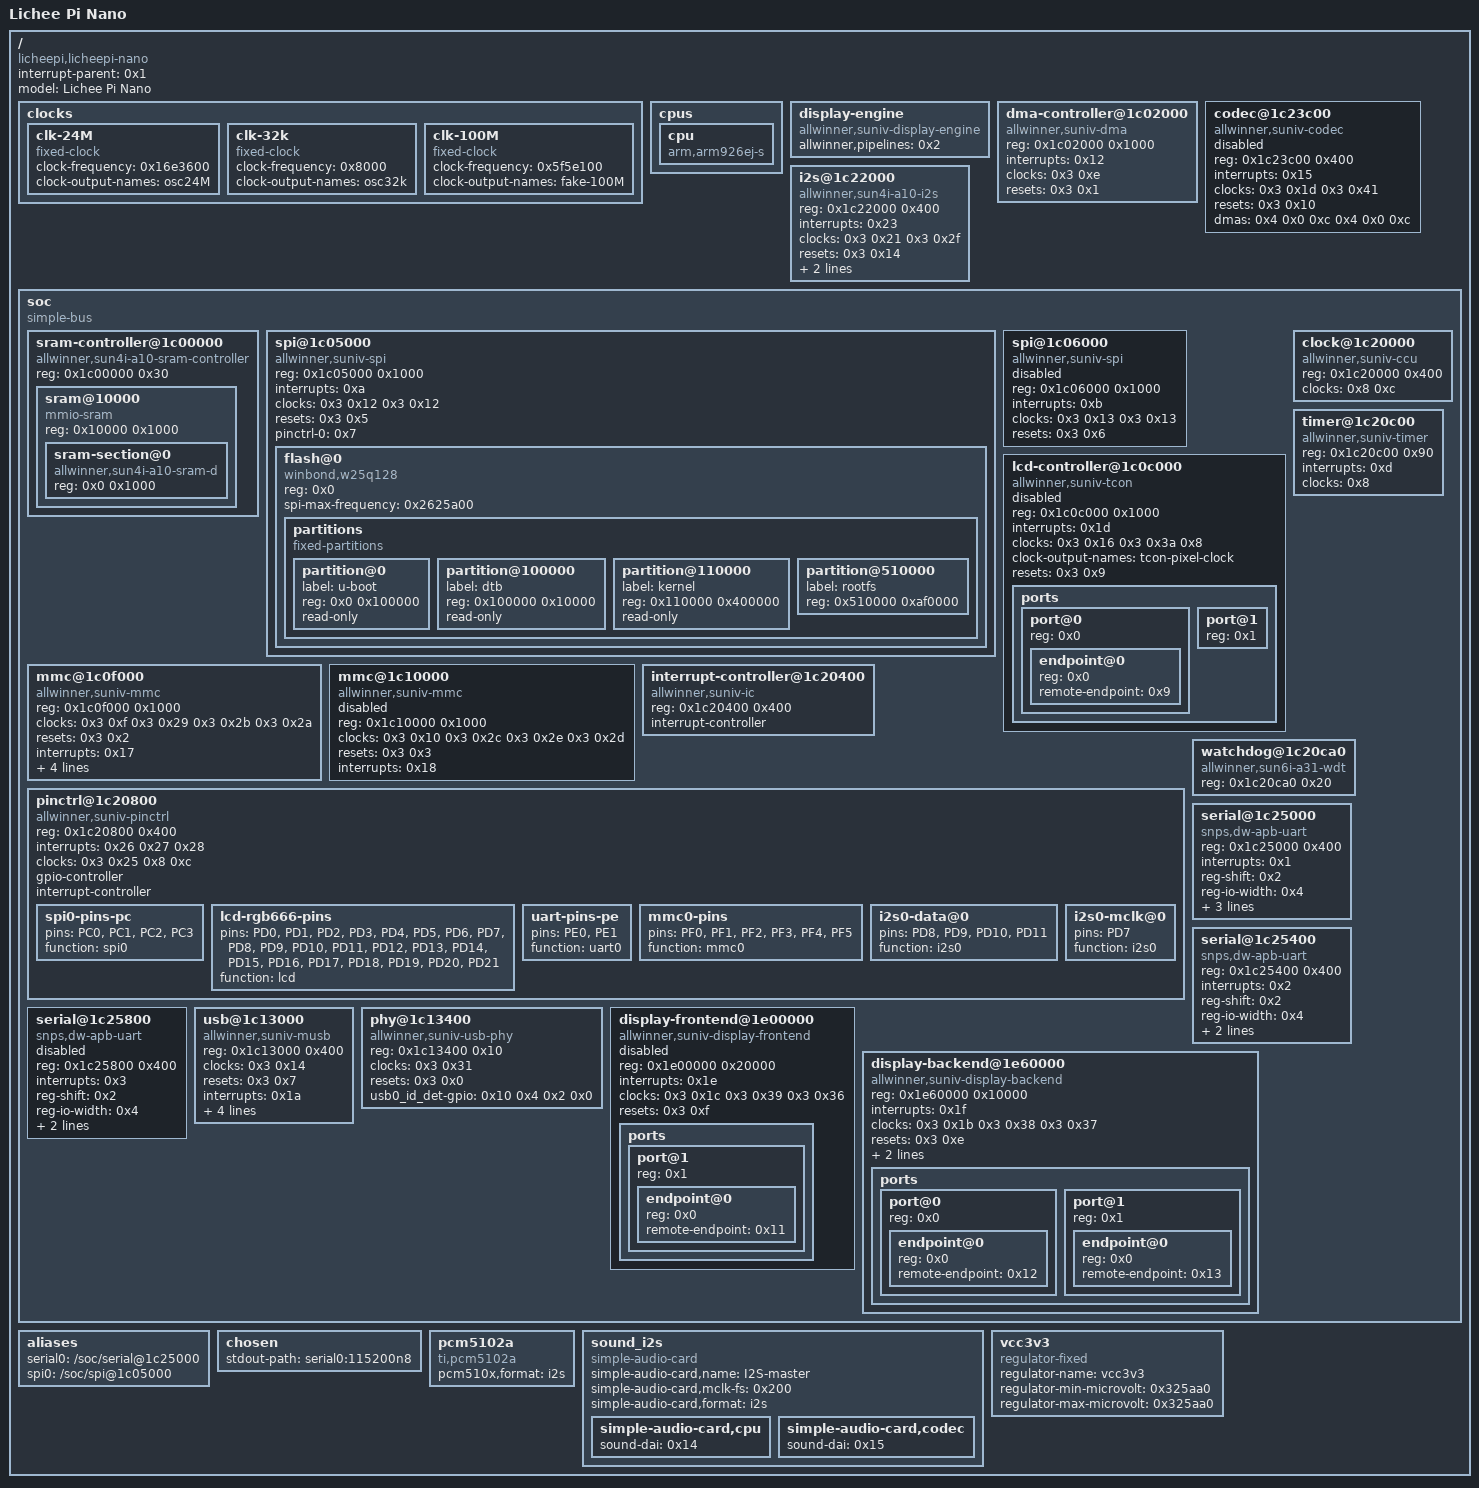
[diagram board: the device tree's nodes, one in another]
/dts-v1/;

/ {
	#address-cells = <0x1>;
	#size-cells = <0x1>;
	interrupt-parent = <0x1>;
	model = "Lichee Pi Nano";
	compatible = "licheepi,licheepi-nano", "allwinner,suniv-f1c100s", "allwinner,suniv";

	clocks {
		#address-cells = <0x1>;
		#size-cells = <0x1>;
		ranges;

		clk-24M {
			#clock-cells = <0x0>;
			compatible = "fixed-clock";
			clock-frequency = <0x16e3600>;
			clock-output-names = "osc24M";
			phandle = <0x8>;
		};

		clk-32k {
			#clock-cells = <0x0>;
			compatible = "fixed-clock";
			clock-frequency = <0x8000>;
			clock-output-names = "osc32k";
			phandle = <0xc>;
		};

		clk-100M {
			#clock-cells = <0x0>;
			compatible = "fixed-clock";
			clock-frequency = <0x5f5e100>;
			clock-output-names = "fake-100M";
		};
	};

	cpus {
		#address-cells = <0x0>;
		#size-cells = <0x0>;

		cpu {
			compatible = "arm,arm926ej-s";
			device_type = "cpu";
		};
	};

	display-engine {
		compatible = "allwinner,suniv-display-engine";
		allwinner,pipelines = <0x2>;
		status = "okay";
	};

	dma-controller@1c02000 {
		compatible = "allwinner,suniv-dma";
		reg = <0x1c02000 0x1000>;
		interrupts = <0x12>;
		clocks = <0x3 0xe>;
		resets = <0x3 0x1>;
		#dma-cells = <0x2>;
		phandle = <0x4>;
	};

	codec@1c23c00 {
		compatible = "allwinner,suniv-codec";
		reg = <0x1c23c00 0x400>;
		interrupts = <0x15>;
		clocks = <0x3 0x1d 0x3 0x41>;
		clock-names = "apb", "codec";
		resets = <0x3 0x10>;
		dmas = <0x4 0x0 0xc 0x4 0x0 0xc>;
		dma-names = "rx", "tx";
		status = "disabled";
	};

	i2s@1c22000 {
		#sound-dai-cells = <0x0>;
		compatible = "allwinner,sun4i-a10-i2s";
		reg = <0x1c22000 0x400>;
		interrupts = <0x23>;
		clocks = <0x3 0x21 0x3 0x2f>;
		clock-names = "apb", "mod";
		resets = <0x3 0x14>;
		dmas = <0x4 0x0 0xc 0x4 0x0 0xc>;
		dma-names = "rx", "tx";
		status = "okay";
		pinctrl-names = "default";
		pinctrl-0 = <0x5 0x6>;
		phandle = <0x14>;
	};

	soc {
		compatible = "simple-bus";
		#address-cells = <0x1>;
		#size-cells = <0x1>;
		ranges;

		sram-controller@1c00000 {
			compatible = "allwinner,sun4i-a10-sram-controller";
			reg = <0x1c00000 0x30>;
			#address-cells = <0x1>;
			#size-cells = <0x1>;
			ranges;

			sram@10000 {
				compatible = "mmio-sram";
				reg = <0x10000 0x1000>;
				#address-cells = <0x1>;
				#size-cells = <0x1>;
				ranges = <0x0 0x10000 0x1000>;

				sram-section@0 {
					compatible = "allwinner,sun4i-a10-sram-d";
					reg = <0x0 0x1000>;
					status = "okay";
					phandle = <0xf>;
				};
			};
		};

		spi@1c05000 {
			compatible = "allwinner,suniv-spi", "allwinner,sun8i-h3-spi";
			reg = <0x1c05000 0x1000>;
			interrupts = <0xa>;
			clocks = <0x3 0x12 0x3 0x12>;
			clock-names = "ahb", "mod";
			resets = <0x3 0x5>;
			status = "okay";
			#address-cells = <0x1>;
			#size-cells = <0x0>;
			pinctrl-names = "default";
			pinctrl-0 = <0x7>;

			flash@0 {
				#address-cells = <0x1>;
				#size-cells = <0x1>;
				compatible = "winbond,w25q128", "jedec,spi-nor";
				reg = <0x0>;
				spi-max-frequency = <0x2625a00>;

				partitions {
					compatible = "fixed-partitions";
					#address-cells = <0x1>;
					#size-cells = <0x1>;

					partition@0 {
						label = "u-boot";
						reg = <0x0 0x100000>;
						read-only;
					};

					partition@100000 {
						label = "dtb";
						reg = <0x100000 0x10000>;
						read-only;
					};

					partition@110000 {
						label = "kernel";
						reg = <0x110000 0x400000>;
						read-only;
					};

					partition@510000 {
						label = "rootfs";
						reg = <0x510000 0xaf0000>;
					};
				};
			};
		};

		spi@1c06000 {
			compatible = "allwinner,suniv-spi", "allwinner,sun8i-h3-spi";
			reg = <0x1c06000 0x1000>;
			interrupts = <0xb>;
			clocks = <0x3 0x13 0x3 0x13>;
			clock-names = "ahb", "mod";
			resets = <0x3 0x6>;
			status = "disabled";
			#address-cells = <0x1>;
			#size-cells = <0x0>;
		};

		lcd-controller@1c0c000 {
			compatible = "allwinner,suniv-tcon";
			reg = <0x1c0c000 0x1000>;
			interrupts = <0x1d>;
			clocks = <0x3 0x16 0x3 0x3a 0x8>;
			clock-names = "ahb", "tcon-ch0", "tcon-ch1";
			clock-output-names = "tcon-pixel-clock";
			resets = <0x3 0x9>;
			reset-names = "lcd";
			status = "disabled";

			ports {
				#address-cells = <0x1>;
				#size-cells = <0x0>;

				port@0 {
					#address-cells = <0x1>;
					#size-cells = <0x0>;
					reg = <0x0>;

					endpoint@0 {
						reg = <0x0>;
						remote-endpoint = <0x9>;
						phandle = <0x13>;
					};
				};

				port@1 {
					#address-cells = <0x1>;
					#size-cells = <0x0>;
					reg = <0x1>;
				};
			};
		};

		mmc@1c0f000 {
			compatible = "allwinner,suniv-mmc", "allwinner,sun7i-a20-mmc";
			reg = <0x1c0f000 0x1000>;
			clocks = <0x3 0xf 0x3 0x29 0x3 0x2b 0x3 0x2a>;
			clock-names = "ahb", "mmc", "output", "sample";
			resets = <0x3 0x2>;
			reset-names = "ahb";
			interrupts = <0x17>;
			pinctrl-names = "default";
			pinctrl-0 = <0xa>;
			status = "okay";
			#address-cells = <0x1>;
			#size-cells = <0x0>;
			vmmc-supply = <0xb>;
			bus-width = <0x4>;
			broken-cd;
		};

		mmc@1c10000 {
			compatible = "allwinner,suniv-mmc", "allwinner,sun7i-a20-mmc";
			reg = <0x1c10000 0x1000>;
			clocks = <0x3 0x10 0x3 0x2c 0x3 0x2e 0x3 0x2d>;
			clock-names = "ahb", "mmc", "output", "sample";
			resets = <0x3 0x3>;
			reset-names = "ahb";
			interrupts = <0x18>;
			status = "disabled";
			#address-cells = <0x1>;
			#size-cells = <0x0>;
		};

		clock@1c20000 {
			compatible = "allwinner,suniv-ccu";
			reg = <0x1c20000 0x400>;
			clocks = <0x8 0xc>;
			clock-names = "hosc", "losc";
			#clock-cells = <0x1>;
			#reset-cells = <0x1>;
			phandle = <0x3>;
		};

		interrupt-controller@1c20400 {
			compatible = "allwinner,suniv-ic";
			reg = <0x1c20400 0x400>;
			interrupt-controller;
			#interrupt-cells = <0x1>;
			phandle = <0x1>;
		};

		pinctrl@1c20800 {
			compatible = "allwinner,suniv-pinctrl";
			reg = <0x1c20800 0x400>;
			interrupts = <0x26 0x27 0x28>;
			clocks = <0x3 0x25 0x8 0xc>;
			clock-names = "apb", "hosc", "losc";
			gpio-controller;
			interrupt-controller;
			#interrupt-cells = <0x3>;
			#gpio-cells = <0x3>;
			phandle = <0x10>;

			spi0-pins-pc {
				pins = "PC0", "PC1", "PC2", "PC3";
				function = "spi0";
				phandle = <0x7>;
			};

			lcd-rgb666-pins {
				pins = "PD0", "PD1", "PD2", "PD3", "PD4", "PD5", "PD6", "PD7", "PD8", "PD9", "PD10", "PD11", "PD12", "PD13", "PD14", "PD15", "PD16", "PD17", "PD18", "PD19", "PD20", "PD21";
				function = "lcd";
			};

			uart-pins-pe {
				pins = "PE0", "PE1";
				function = "uart0";
				phandle = <0xd>;
			};

			mmc0-pins {
				pins = "PF0", "PF1", "PF2", "PF3", "PF4", "PF5";
				function = "mmc0";
				phandle = <0xa>;
			};

			i2s0-data@0 {
				pins = "PD8", "PD9", "PD10", "PD11";
				function = "i2s0";
				phandle = <0x6>;
			};

			i2s0-mclk@0 {
				pins = "PD7";
				function = "i2s0";
				phandle = <0x5>;
			};
		};

		timer@1c20c00 {
			compatible = "allwinner,suniv-timer";
			reg = <0x1c20c00 0x90>;
			interrupts = <0xd>;
			clocks = <0x8>;
		};

		watchdog@1c20ca0 {
			compatible = "allwinner,sun6i-a31-wdt";
			reg = <0x1c20ca0 0x20>;
		};

		serial@1c25000 {
			compatible = "snps,dw-apb-uart";
			reg = <0x1c25000 0x400>;
			interrupts = <0x1>;
			reg-shift = <0x2>;
			reg-io-width = <0x4>;
			clocks = <0x3 0x26>;
			resets = <0x3 0x18>;
			status = "okay";
			pinctrl-names = "default";
			pinctrl-0 = <0xd>;
		};

		serial@1c25400 {
			compatible = "snps,dw-apb-uart";
			reg = <0x1c25400 0x400>;
			interrupts = <0x2>;
			reg-shift = <0x2>;
			reg-io-width = <0x4>;
			clocks = <0x3 0x27>;
			resets = <0x3 0x19>;
			status = "okay";
		};

		serial@1c25800 {
			compatible = "snps,dw-apb-uart";
			reg = <0x1c25800 0x400>;
			interrupts = <0x3>;
			reg-shift = <0x2>;
			reg-io-width = <0x4>;
			clocks = <0x3 0x28>;
			resets = <0x3 0x1a>;
			status = "disabled";
		};

		usb@1c13000 {
			compatible = "allwinner,suniv-musb";
			reg = <0x1c13000 0x400>;
			clocks = <0x3 0x14>;
			resets = <0x3 0x7>;
			interrupts = <0x1a>;
			interrupt-names = "mc";
			phys = <0xe 0x0>;
			phy-names = "usb";
			extcon = <0xe 0x0>;
			allwinner,sram = <0xf 0x1>;
			status = "okay";
			dr_mode = "otg";
		};

		phy@1c13400 {
			compatible = "allwinner,suniv-usb-phy";
			reg = <0x1c13400 0x10>;
			reg-names = "phy_ctrl";
			clocks = <0x3 0x31>;
			clock-names = "usb0_phy";
			resets = <0x3 0x0>;
			reset-names = "usb0_reset";
			#phy-cells = <0x1>;
			status = "okay";
			usb0_id_det-gpio = <0x10 0x4 0x2 0x0>;
			phandle = <0xe>;
		};

		display-frontend@1e00000 {
			compatible = "allwinner,suniv-display-frontend";
			reg = <0x1e00000 0x20000>;
			interrupts = <0x1e>;
			clocks = <0x3 0x1c 0x3 0x39 0x3 0x36>;
			clock-names = "ahb", "mod", "ram";
			resets = <0x3 0xf>;
			status = "disabled";
			phandle = <0x2>;

			ports {
				#address-cells = <0x1>;
				#size-cells = <0x0>;

				port@1 {
					#address-cells = <0x1>;
					#size-cells = <0x0>;
					reg = <0x1>;

					endpoint@0 {
						reg = <0x0>;
						remote-endpoint = <0x11>;
						phandle = <0x12>;
					};
				};
			};
		};

		display-backend@1e60000 {
			compatible = "allwinner,suniv-display-backend";
			reg = <0x1e60000 0x10000>;
			reg-names = "be";
			interrupts = <0x1f>;
			clocks = <0x3 0x1b 0x3 0x38 0x3 0x37>;
			clock-names = "ahb", "mod", "ram";
			resets = <0x3 0xe>;
			reset-names = "be";
			assigned-clocks = <0x3 0x38>;
			assigned-clock-rates = <0x11e1a300>;

			ports {
				#address-cells = <0x1>;
				#size-cells = <0x0>;

				port@0 {
					#address-cells = <0x1>;
					#size-cells = <0x0>;
					reg = <0x0>;

					endpoint@0 {
						reg = <0x0>;
						remote-endpoint = <0x12>;
						phandle = <0x11>;
					};
				};

				port@1 {
					#address-cells = <0x1>;
					#size-cells = <0x0>;
					reg = <0x1>;

					endpoint@0 {
						reg = <0x0>;
						remote-endpoint = <0x13>;
						phandle = <0x9>;
					};
				};
			};
		};
	};

	aliases {
		serial0 = "/soc/serial@1c25000";
		spi0 = "/soc/spi@1c05000";
	};

	chosen {
		stdout-path = "serial0:115200n8";
	};

	pcm5102a {
		#sound-dai-cells = <0x0>;
		compatible = "ti,pcm5102a";
		pcm510x,format = "i2s";
		status = "okay";
		phandle = <0x15>;
	};

	sound_i2s {
		compatible = "simple-audio-card";
		simple-audio-card,name = "I2S-master";
		simple-audio-card,mclk-fs = <0x200>;
		simple-audio-card,format = "i2s";
		status = "okay";

		simple-audio-card,cpu {
			sound-dai = <0x14>;
		};

		simple-audio-card,codec {
			sound-dai = <0x15>;
		};
	};

	vcc3v3 {
		compatible = "regulator-fixed";
		regulator-name = "vcc3v3";
		regulator-min-microvolt = <0x325aa0>;
		regulator-max-microvolt = <0x325aa0>;
		phandle = <0xb>;
	};
};
